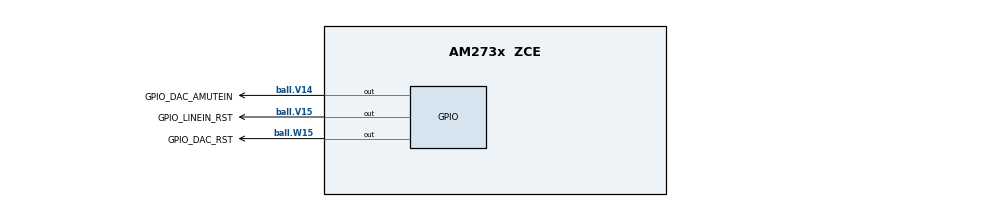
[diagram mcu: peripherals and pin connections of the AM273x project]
/**
 * @cliArgs --device "AM273x" --package "ZCE" --part "Default" --context "c66ss0" --product "MCU_PLUS_SDK@07.03.01"
 * @versions {"tool":"1.13.0+2553"}
 */

/**
 * Import the modules used in this configuration.
 */
const edma      = scripting.addModule("/drivers/edma/edma", {}, false);
const edma1     = edma.addInstance();
const gpio      = scripting.addModule("/drivers/gpio/gpio", {}, false);
const gpio1     = gpio.addInstance();
const gpio2     = gpio.addInstance();
const gpio3     = gpio.addInstance();
const i2c       = scripting.addModule("/drivers/i2c/i2c", {}, false);
const i2c1      = i2c.addInstance();
const mcasp     = scripting.addModule("/drivers/mcasp/mcasp", {}, false);
const mcasp1    = mcasp.addInstance();
const cache_c6x = scripting.addModule("/kernel/dpl/cache_c6x");
const debug_log = scripting.addModule("/kernel/dpl/debug_log");

/**
 * Write custom configuration values to the imported modules.
 */
gpio1.pinDir                    = "OUTPUT";
gpio1.$name                     = "GPIO_DAC_RST";
gpio1.RCSS_GPIO.gpioPin.$assign = "ball.W15";

gpio2.$name                     = "GPIO_DAC_AMUTEIN";
gpio2.pinDir                    = "OUTPUT";
gpio2.RCSS_GPIO.gpioPin.$assign = "ball.V14";

gpio3.$name                     = "GPIO_LINEIN_RST";
gpio3.pinDir                    = "OUTPUT";
gpio3.RCSS_GPIO.gpioPin.$assign = "ball.V15";

i2c1.$name               = "CONFIG_I2C0";
i2c1.instance            = "MSS_I2CA";
i2c1.enableIntr          = false;
i2c1.MSS_I2C.$assign     = "MSS_I2CA";
i2c1.MSS_I2C.SCL.$assign = "ball.U15";
i2c1.MSS_I2C.SCL.$used   = false;
i2c1.MSS_I2C.SDA.$assign = "ball.V16";
i2c1.MSS_I2C.SDA.$used   = false;

mcasp1.$name               = "CONFIG_MCASP0";
mcasp1.enableLoopback      = false;
mcasp1.txCallbackFxn       = "mcasp_txcb";
mcasp1.rxCallbackFxn       = "mcasp_rxcb";
mcasp1.txDataMask          = 0xFFFFFFFF;
mcasp1.txActiveSlotMask    = 0x3;
mcasp1.rxDataMask          = 0xFFFFFFFF;
mcasp1.rxActiveSlotMask    = 0x3;
mcasp1.fsx                 = 48;
mcasp1.fsr                 = 48;
mcasp1.controllerClkx          = 128;
mcasp1.controllerClkr          = 128;
mcasp1.clkSyncMode         = "ASYNC";
mcasp1.RCSS_MCASP.$assign  = "RCSS_MCASPB";
mcasp1.mcaspSer.create(2);
mcasp1.mcaspSer[0].$name   = "CONFIG_MCASP_SER0";
mcasp1.mcaspSer[1].$name   = "CONFIG_MCASP_SER1";
mcasp1.mcaspSer[1].serNum  = 4;
mcasp1.mcaspSer[1].dataDir = "Receive";

debug_log.enableUartLog               = true;
debug_log.uartLog.$name               = "CONFIG_UART0";
debug_log.uartLog.DSS_UART.RX.$assign = "ball.H19";
debug_log.uartLog.DSS_UART.TX.$assign = "ball.J19";

edma1.$name                             = "CONFIG_EDMA0";
mcasp1.edmaConfig                       = edma1;
debug_log.uartLog.edmaConfig            = edma1;
edma1.edmaRmDmaCh[0].$name              = "CONFIG_EDMA_RM0";
edma1.edmaRmDmaCh[0].endIndex           = 63;
edma1.edmaRmQdmaCh[0].$name             = "CONFIG_EDMA_RM1";
edma1.edmaRmTcc[0].$name                = "CONFIG_EDMA_RM2";
edma1.edmaRmTcc[0].endIndex             = 63;
edma1.edmaRmParam[0].$name              = "CONFIG_EDMA_RM3";
edma1.edmaRmReservedDmaCh[0].$name      = "CONFIG_EDMA_RM4";
edma1.edmaRmReservedDmaCh[0].startIndex = 49;
edma1.edmaRmReservedDmaCh[0].endIndex   = 52;

/**
 * Pinmux solution for unlocked pins/peripherals. This ensures that minor changes to the automatic solver in a future
 * version of the tool will not impact the pinmux you originally saw.  These lines can be completely deleted in order to
 * re-solve from scratch.
 */
gpio1.RCSS_GPIO.$suggestSolution            = "RCSS_GPIO0";
gpio2.RCSS_GPIO.$suggestSolution            = "RCSS_GPIO0";
gpio3.RCSS_GPIO.$suggestSolution            = "RCSS_GPIO0";
mcasp1.RCSS_MCASP.FSX.$suggestSolution      = "ball.V13";
mcasp1.RCSS_MCASP.ACLKX.$suggestSolution    = "ball.W14";
mcasp1.RCSS_MCASP.AHCLKX.$suggestSolution   = "ball.V12";
mcasp1.RCSS_MCASP.FSR.$suggestSolution      = "ball.U11";
mcasp1.RCSS_MCASP.ACLKR.$suggestSolution    = "ball.W13";
mcasp1.mcaspSer[0].DAT0.$suggestSolution    = "ball.V11";
mcasp1.mcaspSer[1].DAT4.$suggestSolution    = "ball.T10";
debug_log.uartLog.DSS_UART.$suggestSolution = "DSS_UARTA";
